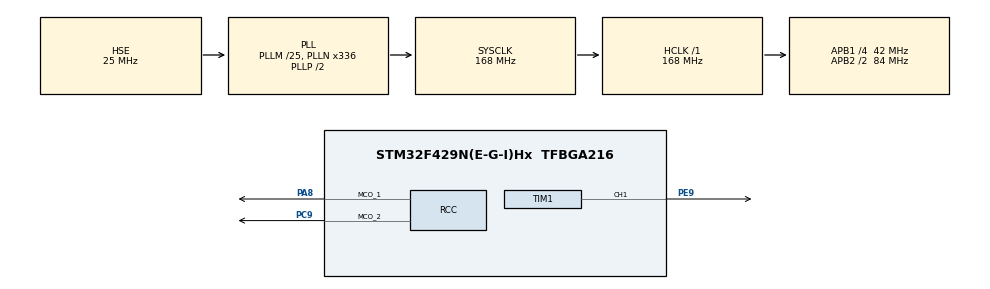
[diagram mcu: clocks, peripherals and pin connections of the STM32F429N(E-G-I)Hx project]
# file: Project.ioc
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Mcu.Family=STM32F4
Mcu.Name=STM32F429N(E-G-I)Hx
Mcu.Package=TFBGA216
NVIC.PriorityGroup=NVIC_PRIORITYGROUP_4
PA8.Mode=Clock-out-1
PA8.Signal=RCC_MCO_1
PC9.Mode=Clock-out-2
PC9.Signal=RCC_MCO_2
PE9.GPIO_ModeDefaultPP=GPIO_MODE_AF_PP
PE9.GPIO_PuPd=GPIO_NOPULL
PE9.GPIO_Speed=GPIO_SPEED_HIGH
PE9.Signal=S_TIM1_CH1
PH0/OSC_IN.Mode=HSE-External-Oscillator
PH0/OSC_IN.Signal=RCC_OSC_IN
PH1/OSC_OUT.Mode=HSE-External-Oscillator
PH1/OSC_OUT.Signal=RCC_OSC_OUT
ProjectManager.TargetToolchain=EWARM 6.70
RCC.48MHZClocksFreq_Value=84000000
RCC.AHBFreq_Value=168000000
RCC.APB1CLKDivider=RCC_HCLK_DIV4
RCC.APB1Freq_Value=42000000
RCC.APB1TimFreq_Value=84000000
RCC.APB2CLKDivider=RCC_HCLK_DIV2
RCC.APB2Freq_Value=84000000
RCC.APB2TimFreq_Value=168000000
RCC.CortexFreq_Value=21000000
RCC.HCLKFreq_Value=168000000
RCC.HSE_VALUE=25000000
RCC.HSI_VALUE=16000000
RCC.LSE_VALUE=32768
RCC.PLLM=25
RCC.PLLN=336
RCC.PLLSourceVirtual=RCC_PLLSOURCE_HSE
RCC.RCC_MCO1Source=RCC_MCO1SOURCE_PLLCLK
RCC.RCC_MCO2Source=RCC_MCO2SOURCE_HSE
RCC.RCC_MCODiv1=RCC_MCODIV_2
RCC.SYSCLKFreq_VALUE=168000000
RCC.SYSCLKSource=RCC_SYSCLKSOURCE_PLLCLK
RCC.VCOOutputFreq_Value=336000000
SH.S_TIM1_CH1.0=TIM1_CH1,PWM Generation1 CH1
TIM1.OCFastMode_PWM-PWM\ Generation1\ CH1=TIM_OCFAST_ENABLE

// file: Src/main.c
/**
  ******************************************************************************
  * File Name          : main.c
  * Date               : 29/10/2014 18:30:23
  * Description        : Main program body
  ******************************************************************************
  *
  * COPYRIGHT(c) 2014 STMicroelectronics
  *
  * Redistribution and use in source and binary forms, with or without modification,
  * are permitted provided that the following conditions are met:
  *   1. Redistributions of source code must retain the above copyright notice,
  *      this list of conditions and the following disclaimer.
  *   2. Redistributions in binary form must reproduce the above copyright notice,
  *      this list of conditions and the following disclaimer in the documentation
  *      and/or other materials provided with the distribution.
  *   3. Neither the name of STMicroelectronics nor the names of its contributors
  *      may be used to endorse or promote products derived from this software
  *      without specific prior written permission.
  *
  * THIS SOFTWARE IS PROVIDED BY THE COPYRIGHT HOLDERS AND CONTRIBUTORS "AS IS"
  * AND ANY EXPRESS OR IMPLIED WARRANTIES, INCLUDING, BUT NOT LIMITED TO, THE
  * IMPLIED WARRANTIES OF MERCHANTABILITY AND FITNESS FOR A PARTICULAR PURPOSE ARE
  * DISCLAIMED. IN NO EVENT SHALL THE COPYRIGHT HOLDER OR CONTRIBUTORS BE LIABLE
  * FOR ANY DIRECT, INDIRECT, INCIDENTAL, SPECIAL, EXEMPLARY, OR CONSEQUENTIAL
  * DAMAGES (INCLUDING, BUT NOT LIMITED TO, PROCUREMENT OF SUBSTITUTE GOODS OR
  * SERVICES; LOSS OF USE, DATA, OR PROFITS; OR BUSINESS INTERRUPTION) HOWEVER
  * CAUSED AND ON ANY THEORY OF LIABILITY, WHETHER IN CONTRACT, STRICT LIABILITY,
  * OR TORT (INCLUDING NEGLIGENCE OR OTHERWISE) ARISING IN ANY WAY OUT OF THE USE
  * OF THIS SOFTWARE, EVEN IF ADVISED OF THE POSSIBILITY OF SUCH DAMAGE.
  *
  ******************************************************************************
  */

#include "stm32f4xx_hal.h"

/* USER CODE BEGIN Includes */
#include "stm324x9i_eval.h"
#include "stm324x9i_eval_io.h"
#include "stm324x9i_eval_lcd.h"
#include "stm324x9i_eval_ts.h"
#include "lcd_log.h"
#include "stdlib.h"
#include "background.h"
#include "string.h"
#include "math.h"
/* USER CODE END Includes */

TIM_HandleTypeDef htim1;

/* USER CODE BEGIN PV */
char buffer_HZ[4] = "000";
char buffer_KHZ[4] = "000";
char buffer_MHZ[4] = "000";
int counter = 0;
int multiplier = 1;
int frequency = 0;
TS_StateTypeDef cord;
uint16_t y ;
uint16_t x;
int counter_start = 0;
char frequency_c[20];
char frequency_display[20];
int multiplier_keyboard = 10;
int last_add = 0;
/* USER CODE END PV */

void SystemClock_Config(void);
static void MX_GPIO_Init(void);
static void MX_TIM1_Init(void);

/* USER CODE BEGIN PFP */
void GetFrequency(void);
void TimerUpdate(int frequency);
void frequency_displayer(int frequency);
/* USER CODE END PFP */

/* USER CODE BEGIN 0 */
#define USE_JOYSTICK
/* USER CODE END 0 */

int main(void)
{

  /* MCU Configuration----------------------------------------------------------*/

  /* Reset of all peripherals, Initializes the Flash interface and the Systick. */
  HAL_Init();

  /* Configure the system clock */
  SystemClock_Config();

  /* Initialize all configured peripherals */
  MX_GPIO_Init();
  MX_TIM1_Init();

  /* USER CODE BEGIN 2 */
  BSP_JOY_Init(JOY_MODE_EXTI);
  BSP_PB_Init(BUTTON_TAMPER, BUTTON_MODE_EXTI);

  BSP_IO_Init();
  BSP_LCD_Init();
  BSP_TS_Init(BSP_LCD_GetXSize(), BSP_LCD_GetYSize());
  BSP_TS_ITConfig();

  BSP_LCD_LayerDefaultInit(0, LCD_FB_START_ADDRESS);
  BSP_LCD_SelectLayer(0);

  BSP_LCD_DisplayOn();
  LCD_LOG_Init();

  BSP_LCD_Clear(LCD_COLOR_BLACK);

  BSP_LCD_SetTextColor(LCD_COLOR_BLACK);
  BSP_LCD_SetBackColor(LCD_COLOR_RED);
  BSP_LCD_DrawBitmap(0, 0, (uint8_t *)background);
  BSP_LCD_SetFont(&Font20);
  BSP_LCD_SetTextColor(LCD_COLOR_BLACK);
  BSP_LCD_SetBackColor(LCD_COLOR_WHITE);

  frequency = 10000;
  multiplier = 10000;
  TimerUpdate(frequency);

  frequency_displayer( frequency);
  BSP_LCD_DisplayStringAtLine(3, (uint8_t *)frequency_display);
  BSP_LCD_DisplayStringAtLine(5, (uint8_t *)frequency_display);
  BSP_LCD_SetFont(&Font16);
  BSP_LCD_DisplayStringAtLine(12, (uint8_t *)"OFF");
  BSP_LCD_DisplayStringAtLine(10, (uint8_t *)"10 KHz");
  BSP_LCD_SetFont(&Font20);

  BSP_LED_Init(LED1);
  BSP_LED_Init(LED2);
  BSP_LED_Init(LED4);
  BSP_LED_On(LED2);
  BSP_LED_Off(LED1);
  BSP_LED_Off(LED4);

  /* USER CODE END 2 */

  while (1)
  {
  }

}

/** System Clock Configuration
*/
void SystemClock_Config(void)
{

  RCC_OscInitTypeDef RCC_OscInitStruct;
  RCC_ClkInitTypeDef RCC_ClkInitStruct;

  __PWR_CLK_ENABLE();

  __HAL_PWR_VOLTAGESCALING_CONFIG(PWR_REGULATOR_VOLTAGE_SCALE1);

  RCC_OscInitStruct.OscillatorType = RCC_OSCILLATORTYPE_HSE;
  RCC_OscInitStruct.HSEState = RCC_HSE_ON;
  RCC_OscInitStruct.PLL.PLLState = RCC_PLL_ON;
  RCC_OscInitStruct.PLL.PLLSource = RCC_PLLSOURCE_HSE;
  RCC_OscInitStruct.PLL.PLLM = 25;
  RCC_OscInitStruct.PLL.PLLN = 336;
  RCC_OscInitStruct.PLL.PLLP = RCC_PLLP_DIV2;
  RCC_OscInitStruct.PLL.PLLQ = 4;
  HAL_RCC_OscConfig(&RCC_OscInitStruct);

  RCC_ClkInitStruct.ClockType = RCC_CLOCKTYPE_SYSCLK|RCC_CLOCKTYPE_PCLK1
                              |RCC_CLOCKTYPE_PCLK2;
  RCC_ClkInitStruct.SYSCLKSource = RCC_SYSCLKSOURCE_PLLCLK;
  RCC_ClkInitStruct.AHBCLKDivider = RCC_SYSCLK_DIV1;
  RCC_ClkInitStruct.APB1CLKDivider = RCC_HCLK_DIV4;
  RCC_ClkInitStruct.APB2CLKDivider = RCC_HCLK_DIV2;
  HAL_RCC_ClockConfig(&RCC_ClkInitStruct, FLASH_LATENCY_5);

}

/* TIM1 init function */
void MX_TIM1_Init(void)
{

  TIM_OC_InitTypeDef sConfigOC;

  htim1.Instance = TIM1;
  htim1.Init.Prescaler = 0;
  htim1.Init.CounterMode = TIM_COUNTERMODE_UP;
  htim1.Init.Period = 0x0;
  htim1.Init.ClockDivision = TIM_CLOCKDIVISION_DIV4;
  htim1.Init.RepetitionCounter = 0;
  HAL_TIM_PWM_Init(&htim1);

  sConfigOC.OCMode = TIM_OCMODE_PWM1;
  sConfigOC.Pulse = 0x0;
  sConfigOC.OCPolarity = TIM_OCPOLARITY_HIGH;
  sConfigOC.OCNPolarity = TIM_OCNPOLARITY_HIGH;
  sConfigOC.OCFastMode = TIM_OCFAST_ENABLE;
  sConfigOC.OCIdleState = TIM_OCIDLESTATE_RESET;
  sConfigOC.OCNIdleState = TIM_OCNIDLESTATE_RESET;
  HAL_TIM_PWM_ConfigChannel(&htim1, &sConfigOC, TIM_CHANNEL_1);

}

/** Configure pins
     PC9   ------> RCC_MCO_2
     PA8   ------> RCC_MCO_1
*/
void MX_GPIO_Init(void)
{
  /* GPIO Ports Clock Enable */
  __GPIOC_CLK_ENABLE();
  __GPIOA_CLK_ENABLE();
  __GPIOH_CLK_ENABLE();
  __GPIOE_CLK_ENABLE();
}

/* USER CODE BEGIN 4 */

void HAL_GPIO_EXTI_Callback(uint16_t gpio)
{
  if (gpio == GPIO_PIN_8)
  {
  GetFrequency();
  }
}

void GetFrequency(void)
{

  BSP_TS_GetState(&cord);

  y = cord.y;
  x = cord.x;

  BSP_LED_On(LED4);

if (cord.TouchDetected == 1)
{
  if ((y>=228) && (y<=260))
  {
    if ((x>=1) && (x<=46))
    {
      multiplier = 10000000;
      BSP_LCD_SetFont(&Font16);
      BSP_LCD_DisplayStringAtLine(10, (uint8_t *)"             ");
      BSP_LCD_DisplayStringAtLine(10, (uint8_t *)"10 MHz");
      BSP_LCD_SetFont(&Font20);

    }
        if ((x>=46) && (x<=72))
    {
      multiplier = 1000000;
      BSP_LCD_SetFont(&Font16);
      BSP_LCD_DisplayStringAtLine(10, (uint8_t *)"             ");
      BSP_LCD_DisplayStringAtLine(10, (uint8_t *)"1 MHz");
      BSP_LCD_SetFont(&Font20);
    }
        if ((x>=72) && (x<=108))
    {
      multiplier = 100000;
      BSP_LCD_SetFont(&Font16);
      BSP_LCD_DisplayStringAtLine(10, (uint8_t *)"             ");
      BSP_LCD_DisplayStringAtLine(10, (uint8_t *)"100 KHz");
      BSP_LCD_SetFont(&Font20);
    }
        if ((x>=108) && (x<=140))
    {
      multiplier = 10000;
      BSP_LCD_SetFont(&Font16);
      BSP_LCD_DisplayStringAtLine(10, (uint8_t *)"             ");
      BSP_LCD_DisplayStringAtLine(10, (uint8_t *)"10 KHz");
      BSP_LCD_SetFont(&Font20);
    }
        if ((x>=140) && (x<=174))
    {
      multiplier = 1000;
      BSP_LCD_SetFont(&Font16);
      BSP_LCD_DisplayStringAtLine(10, (uint8_t *)"             ");
      BSP_LCD_DisplayStringAtLine(10, (uint8_t *)"1 KHz");
      BSP_LCD_SetFont(&Font20);
    }
        if ((x>=174) && (x<=207))
    {
      multiplier = 100;
      BSP_LCD_SetFont(&Font16);
      BSP_LCD_DisplayStringAtLine(10, (uint8_t *)"             ");
      BSP_LCD_DisplayStringAtLine(10, (uint8_t *)"100 Hz");
      BSP_LCD_SetFont(&Font20);
    }
        if ((x>=207) && (x<=232))
    {
      multiplier = 10;
      BSP_LCD_SetFont(&Font16);
      BSP_LCD_DisplayStringAtLine(10, (uint8_t *)"             ");
      BSP_LCD_DisplayStringAtLine(10, (uint8_t *)"10 Hz");
      BSP_LCD_SetFont(&Font20);
    }
        if ((x>=232) && (x<=261))
    {
      multiplier = 1;
      BSP_LCD_SetFont(&Font16);
      BSP_LCD_DisplayStringAtLine(10, (uint8_t *)"             ");
      BSP_LCD_DisplayStringAtLine(10, (uint8_t *)"1 Hz");
      BSP_LCD_SetFont(&Font20);
    }

    if ((x>=261) && (x <= 430))
    {
      if (counter_start == 0)
      {
        HAL_TIM_PWM_Start(&htim1, TIM_CHANNEL_1);
        counter_start++;
        BSP_LCD_SetFont(&Font16);
        BSP_LCD_DisplayStringAtLine(12, (uint8_t *)"             ");
        BSP_LCD_DisplayStringAtLine(12, (uint8_t *)"ON");
        BSP_LCD_SetFont(&Font20);
        BSP_LED_On(LED1);
        BSP_LED_Off(LED2);
      }
      else
      {
        HAL_TIM_PWM_Stop(&htim1, TIM_CHANNEL_1);
        counter_start--;
        BSP_LCD_SetFont(&Font16);
        BSP_LCD_DisplayStringAtLine(12, (uint8_t *)"             ");
        BSP_LCD_DisplayStringAtLine(12, (uint8_t *)"OFF");
        BSP_LCD_SetFont(&Font20);
        BSP_LED_On(LED2);
        BSP_LED_Off(LED1);
      }
    }
  }

  if ((x>=418) && (x<=460))
  {
    if ((y>=38) && (y<=84))
    {
      frequency = frequency + multiplier;
      frequency_displayer(frequency);
      BSP_LCD_DisplayStringAtLine(5, (uint8_t *)"                 ");
      BSP_LCD_DisplayStringAtLine(5, (uint8_t *)frequency_display);

    }
    if ((y>=84) && (y<=142))
    {
      frequency = frequency - multiplier;
      if (frequency < 0)
      {
        frequency = 0;
      }

      frequency_displayer( frequency);
      BSP_LCD_DisplayStringAtLine(5, (uint8_t *)"                 ");
      BSP_LCD_DisplayStringAtLine(5, (uint8_t *)frequency_display);
    }

    if ((y>=142) && (y<=180))
    {
      TimerUpdate(frequency);
      frequency_displayer( frequency);
      BSP_LCD_DisplayStringAtLine(3, (uint8_t *)"                 ");
      BSP_LCD_DisplayStringAtLine(3, (uint8_t *)frequency_display);
    }
    if ((y>=184) && (y<=272))
    {
      frequency = 0;
      frequency_displayer( 0);
      BSP_LCD_DisplayStringAtLine(5, (uint8_t *)"                 ");
      BSP_LCD_DisplayStringAtLine(5, (uint8_t *)frequency_display);

    }
  }

  if ((x>=285) && (x<=375))
  {
    if ((y>=60) && (y<=190))
    {

      if ((x>=285) && (x<=310))
      {
        if ((y>=65) && (y<=90))
        {

          frequency = 1 + (frequency * multiplier_keyboard);
          frequency_displayer( frequency);
          BSP_LCD_DisplayStringAtLine(5, (uint8_t *)"                 ");
          BSP_LCD_DisplayStringAtLine(5, (uint8_t *)frequency_display);
          last_add = 1;

        }
        if ((y>=100) && (y<=120))
        {

          frequency = 4 + (frequency * multiplier_keyboard);
          frequency_displayer( frequency);
          BSP_LCD_DisplayStringAtLine(5, (uint8_t *)"                 ");
          BSP_LCD_DisplayStringAtLine(5, (uint8_t *)frequency_display);
          last_add = 4;

        }
        if ((y>=130) && (y<=155))
        {

          frequency = 7 + (frequency * multiplier_keyboard);
          frequency_displayer( frequency);
          BSP_LCD_DisplayStringAtLine(5, (uint8_t *)"                 ");
          BSP_LCD_DisplayStringAtLine(5, (uint8_t *)frequency_display);
          last_add = 7;

        }

        if ((y>=165) && (y<=185))
        {

          frequency = (frequency )/multiplier_keyboard;
          frequency_displayer( frequency);
          BSP_LCD_DisplayStringAtLine(5, (uint8_t *)"                 ");
          BSP_LCD_DisplayStringAtLine(5, (uint8_t *)frequency_display);

        }
      }

      if ((x>=318) && (x<=345))
      {
        if ((y>=65) && (y<=90))
        {

          frequency = 2 + (frequency * multiplier_keyboard);
          frequency_displayer( frequency);
          BSP_LCD_DisplayStringAtLine(5, (uint8_t *)"                 ");
          BSP_LCD_DisplayStringAtLine(5, (uint8_t *)frequency_display);
          last_add = 2;

        }
        if ((y>=100) && (y<=120))
        {

          frequency = 5 + (frequency * multiplier_keyboard);
          frequency_displayer( frequency);
          BSP_LCD_DisplayStringAtLine(5, (uint8_t *)"                 ");
          BSP_LCD_DisplayStringAtLine(5, (uint8_t *)frequency_display);
          last_add = 5;

        }
        if ((y>=130) && (y<=155))
        {

          frequency = 8 + (frequency * multiplier_keyboard);
          frequency_displayer( frequency);
          BSP_LCD_DisplayStringAtLine(5, (uint8_t *)"                 ");
          BSP_LCD_DisplayStringAtLine(5, (uint8_t *)frequency_display);
          last_add = 8;

        }
        if ((y>=165) && (y<=185))
        {

          frequency = 0 + (frequency * multiplier_keyboard);
          frequency_displayer( frequency);
          BSP_LCD_DisplayStringAtLine(5, (uint8_t *)"                 ");
          BSP_LCD_DisplayStringAtLine(5, (uint8_t *)frequency_display);
          last_add = 0;

        }
      }

      if ((x>=350) && (x<=375))
      {
        if ((y>=65) && (y<=90))
        {

          frequency = 3 + (frequency * multiplier_keyboard);
          frequency_displayer( frequency);
          BSP_LCD_DisplayStringAtLine(5, (uint8_t *)"                 ");
          BSP_LCD_DisplayStringAtLine(5, (uint8_t *)frequency_display);
          last_add = 3;

        }
        if ((y>=100) && (y<=120))
        {

          frequency = 6 + (frequency * multiplier_keyboard);
          frequency_displayer( frequency);
          BSP_LCD_DisplayStringAtLine(5, (uint8_t *)"                 ");
          BSP_LCD_DisplayStringAtLine(5, (uint8_t *)frequency_display);
          last_add = 6;

        }
        if ((y>=130) && (y<=155))
        {

          frequency = 9 + (frequency * multiplier_keyboard);
          frequency_displayer( frequency);
          BSP_LCD_DisplayStringAtLine(5, (uint8_t *)"                 ");
          BSP_LCD_DisplayStringAtLine(5, (uint8_t *)frequency_display);
          last_add = 9;

        }
        if ((y>=165) && (y<=185))
        {

          TimerUpdate(frequency);
          frequency_displayer( frequency);
          BSP_LCD_DisplayStringAtLine(3, (uint8_t *)"                 ");
          BSP_LCD_DisplayStringAtLine(3, (uint8_t *)frequency_display);
        }
      }
    }
  }
}
#ifdef USE_JOYSTICK
  switch(BSP_JOY_GetState())
  {

  case JOY_SEL:

    TimerUpdate(frequency);
    frequency_displayer( frequency);
    BSP_LCD_DisplayStringAtLine(3, (uint8_t *)"                 ");
    BSP_LCD_DisplayStringAtLine(3, (uint8_t *)frequency_display);

  break;

  case JOY_LEFT:
          counter++;

    if( counter ==0 )
    {
      multiplier = 1;
      BSP_LCD_SetFont(&Font16);
      BSP_LCD_DisplayStringAtLine(10, (uint8_t *)"             ");
      BSP_LCD_DisplayStringAtLine(10, (uint8_t *)"1 Hz");
      BSP_LCD_SetFont(&Font20);
    }

    else if( counter ==1)
    {
      multiplier = 10;
      BSP_LCD_SetFont(&Font16);
      BSP_LCD_DisplayStringAtLine(10, (uint8_t *)"             ");
      BSP_LCD_DisplayStringAtLine(10, (uint8_t *)"10 Hz");
      BSP_LCD_SetFont(&Font20);
    }

    else if( counter ==2)
    {
      multiplier = 100;
      BSP_LCD_SetFont(&Font16);
      BSP_LCD_DisplayStringAtLine(10, (uint8_t *)"             ");
      BSP_LCD_DisplayStringAtLine(10, (uint8_t *)"100 Hz");
      BSP_LCD_SetFont(&Font20);
    }
    else if( counter ==3)
    {
      multiplier = 1000;
      BSP_LCD_SetFont(&Font16);
      BSP_LCD_DisplayStringAtLine(10, (uint8_t *)"             ");
      BSP_LCD_DisplayStringAtLine(10, (uint8_t *)"1 KHz");
      BSP_LCD_SetFont(&Font20);
    }

    else if( counter ==4)
    {
      multiplier = 10000;
      BSP_LCD_SetFont(&Font16);
      BSP_LCD_DisplayStringAtLine(10, (uint8_t *)"             ");
      BSP_LCD_DisplayStringAtLine(10, (uint8_t *)"10 KHz");
      BSP_LCD_SetFont(&Font20);
    }
    else if( counter ==5)
    {
      multiplier = 100000;
      BSP_LCD_SetFont(&Font16);
      BSP_LCD_DisplayStringAtLine(10, (uint8_t *)"             ");
      BSP_LCD_DisplayStringAtLine(10, (uint8_t *)"100 KHz");
      BSP_LCD_SetFont(&Font20);
    }

    else if( counter ==6)
    {
      multiplier = 1000000;
      BSP_LCD_SetFont(&Font16);
      BSP_LCD_DisplayStringAtLine(10, (uint8_t *)"             ");
      BSP_LCD_DisplayStringAtLine(10, (uint8_t *)"1 MHz");
      BSP_LCD_SetFont(&Font20);
    }

    else if( counter ==7)
    {
      multiplier = 10000000;
      BSP_LCD_SetFont(&Font16);
      BSP_LCD_DisplayStringAtLine(10, (uint8_t *)"             ");
      BSP_LCD_DisplayStringAtLine(10, (uint8_t *)"10 MHz");
      BSP_LCD_SetFont(&Font20);
    }

    else if( counter >7)
    {
      multiplier = 1;
      counter = 0;
      BSP_LCD_SetFont(&Font16);
      BSP_LCD_DisplayStringAtLine(10, (uint8_t *)"             ");
      BSP_LCD_DisplayStringAtLine(10, (uint8_t *)"1 Hz");
      BSP_LCD_SetFont(&Font20);

    }

  break;

  case JOY_RIGHT:

    counter--;
    if( counter ==0 )
    {
      multiplier = 1;
      BSP_LCD_SetFont(&Font16);
      BSP_LCD_DisplayStringAtLine(10, (uint8_t *)"             ");
      BSP_LCD_DisplayStringAtLine(10, (uint8_t *)"1 Hz");
      BSP_LCD_SetFont(&Font20);
    }

    else if( counter ==1)
    {
      multiplier = 10;
      BSP_LCD_SetFont(&Font16);
      BSP_LCD_DisplayStringAtLine(10, (uint8_t *)"             ");
      BSP_LCD_DisplayStringAtLine(10, (uint8_t *)"10 Hz");
      BSP_LCD_SetFont(&Font20);
    }

    else if( counter ==2)
    {
      multiplier = 100;
      BSP_LCD_SetFont(&Font16);
      BSP_LCD_DisplayStringAtLine(10, (uint8_t *)"             ");
      BSP_LCD_DisplayStringAtLine(10, (uint8_t *)"100 Hz");
      BSP_LCD_SetFont(&Font20);
    }
    else if( counter ==3)
    {
      multiplier = 1000;
      BSP_LCD_SetFont(&Font16);
      BSP_LCD_DisplayStringAtLine(10, (uint8_t *)"             ");
      BSP_LCD_DisplayStringAtLine(10, (uint8_t *)"1 KHz");
      BSP_LCD_SetFont(&Font20);
    }

    else if( counter ==4)
    {
      multiplier = 10000;
      BSP_LCD_SetFont(&Font16);
      BSP_LCD_DisplayStringAtLine(10, (uint8_t *)"             ");
      BSP_LCD_DisplayStringAtLine(10, (uint8_t *)"10 KHz");
      BSP_LCD_SetFont(&Font20);
    }
    else if( counter ==5)
    {
      multiplier = 100000;
      BSP_LCD_SetFont(&Font16);
      BSP_LCD_DisplayStringAtLine(10, (uint8_t *)"             ");
      BSP_LCD_DisplayStringAtLine(10, (uint8_t *)"100 KHz");
      BSP_LCD_SetFont(&Font20);
    }

    else if( counter ==6)
    {
      multiplier = 1000000;
      BSP_LCD_SetFont(&Font16);
      BSP_LCD_DisplayStringAtLine(10, (uint8_t *)"             ");
      BSP_LCD_DisplayStringAtLine(10, (uint8_t *)"1 MHz");
      BSP_LCD_SetFont(&Font20);
    }

    else if( counter ==7)
    {
      multiplier = 10000000;
      BSP_LCD_SetFont(&Font16);
      BSP_LCD_DisplayStringAtLine(10, (uint8_t *)"             ");
      BSP_LCD_DisplayStringAtLine(10, (uint8_t *)"10 MHz");
      BSP_LCD_SetFont(&Font20);
    }

    else if( counter < 0)
    {
      multiplier = 10000000;
      counter = 7;
      BSP_LCD_SetFont(&Font16);
      BSP_LCD_DisplayStringAtLine(10, (uint8_t *)"             ");
      BSP_LCD_DisplayStringAtLine(10, (uint8_t *)"10 MHz");
      BSP_LCD_SetFont(&Font20);
    }
    break;

  case JOY_DOWN:

    frequency = frequency - multiplier;
    frequency_displayer( frequency);
    BSP_LCD_DisplayStringAtLine(5, (uint8_t *)"                 ");
    BSP_LCD_DisplayStringAtLine(5, (uint8_t *)frequency_display);
    last_add = 0;
  break;

  case JOY_UP:
    frequency = frequency + multiplier;
    frequency_displayer( frequency);
    BSP_LCD_DisplayStringAtLine(5, (uint8_t *)"                 ");
    BSP_LCD_DisplayStringAtLine(5, (uint8_t *)frequency_display);
    last_add = 0;
  break;

  default:
    break;

  }
#endif

}

/** void timerupdate
   * @brief
*/
void TimerUpdate(int frequency)
{
  int prescaler = 0;
  int TimFrequency = 168000000;

  while (((TimFrequency/(prescaler+1))/(frequency)) >= 0xFFFF)
  {
    prescaler ++;
  }

  TIM1->PSC = (prescaler);
  TIM1->ARR = ((TimFrequency/(prescaler+1))/(frequency))-1;
  TIM1->CCR1 = (TIM1->ARR)/2;
  BSP_LED_Off(LED4);

}

void frequency_displayer(int frequency)
{

  int divider = 1;
  while ((frequency / divider)>=1)
  {
    divider = divider * 10;
  }

  divider = divider / 10;

  if (divider >= 1000000)
  {
    sprintf(frequency_display,"%.6f",(float)frequency/1000000);
    strcat(frequency_display, "  MHz");
  }

  else if (divider >= 1000)
  {
    sprintf(frequency_display,"%.3f",(float)frequency/1000);
    strcat(frequency_display, "  KHz");
  }

  else
  {
    sprintf(frequency_display,"%d",frequency);
    strcat(frequency_display, "  Hz");
  }

}
/* USER CODE END 4 */

/************************ (C) COPYRIGHT STMicroelectronics *****END OF FILE****/
